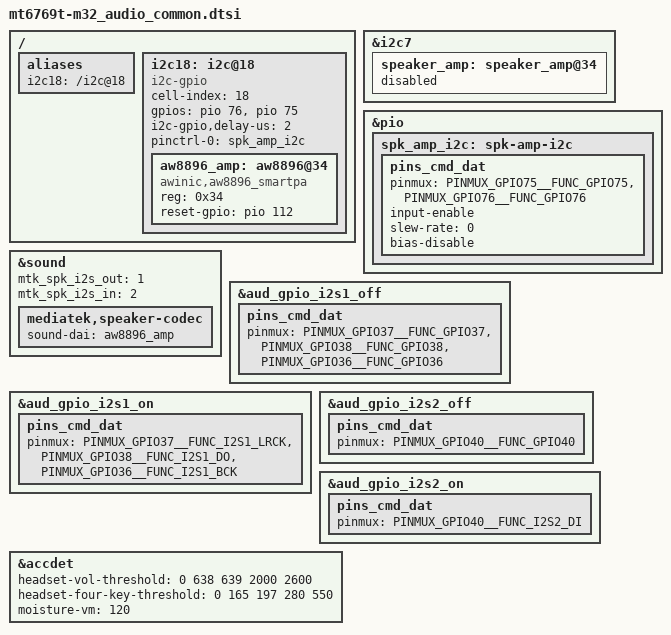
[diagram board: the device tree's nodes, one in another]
/*
 * SAMSUNG board device tree source
 *
 * Copyright (c) 2020 Samsung Electronics Co., Ltd.
 *		http://www.samsung.com
 *
 * This program is free software; you can redistribute it and/or modify
 * it under the terms of the GNU General Public License version 2 as
 * published by the Free Software Foundation.
 */

&i2c7 {
	speaker_amp: speaker_amp@34 {
		status = "disabled";
	};
};

/ {
	fragment@model {
		target-path = "/";
		__overlay__ {
			aliases {
				i2c18 = "/i2c@18";
			};

			/* SMA1305 SPK AMP */
			i2c18: i2c@18 {
				cell-index = <18>;
				status = "okay";
				compatible = "i2c-gpio";
				gpios = <&pio 76 0 /* sda */
					&pio 75 0>; /* scl */
				i2c-gpio,delay-us = <2>;

				#address-cells = <1>;
				#size-cells = <0>;
				pinctrl-names = "default";
				pinctrl-0 = <&spk_amp_i2c>;

				aw8896_amp: aw8896@34 {
					#sound-dai-cells = <0>;
					compatible = "awinic,aw8896_smartpa";
					reg = <0x34>;
					reset-gpio = <&pio 112 0>;
					status = "okay";
				};
			};
		};
	};
};

&pio {
	spk_amp_i2c: spk-amp-i2c {
		pins_cmd_dat {
			pinmux = <PINMUX_GPIO75__FUNC_GPIO75>, /* SPK_AMP_I2C_SCL_1P8 */
				<PINMUX_GPIO76__FUNC_GPIO76>; /* SPK_AMP_I2C_SDA_1P8 */
			input-enable;
			slew-rate = <0>;
			bias-disable;
		};
	};
};

&sound {
	mtk_spk_i2s_out = <1>;
	mtk_spk_i2s_in = <2>;
	mediatek,speaker-codec {
		sound-dai = <&aw8896_amp>;
	};
};

/* I2S gpio configuration */
&aud_gpio_i2s1_off {
	pins_cmd_dat {
		pinmux = <PINMUX_GPIO37__FUNC_GPIO37>,
			 <PINMUX_GPIO38__FUNC_GPIO38>,
			 <PINMUX_GPIO36__FUNC_GPIO36>;
	};
};

&aud_gpio_i2s1_on {
	pins_cmd_dat {
		pinmux = <PINMUX_GPIO37__FUNC_I2S1_LRCK>,
			 <PINMUX_GPIO38__FUNC_I2S1_DO>,
			 <PINMUX_GPIO36__FUNC_I2S1_BCK>;
	};
};

&aud_gpio_i2s2_off {
	pins_cmd_dat {
		pinmux = <PINMUX_GPIO40__FUNC_GPIO40>;
	};
};

&aud_gpio_i2s2_on {
	pins_cmd_dat {
		pinmux = <PINMUX_GPIO40__FUNC_I2S2_DI>;
	};
};

&accdet {
	/*min_3pole--max_3pole--min_4pole--max_4pole--vol_bias*/
	headset-vol-threshold = <0 638 639 2000 2600>;
	/*0--MD_MAX--VOICE_MAX--UP_MAX--DW_MAX*/
	headset-four-key-threshold = <0 165 197 280 550>;

	/* moisture SW mode config start, use external resister or not.
	 */
	moisture-vm = <120>;
	/* moisture SW mode config end */
};
